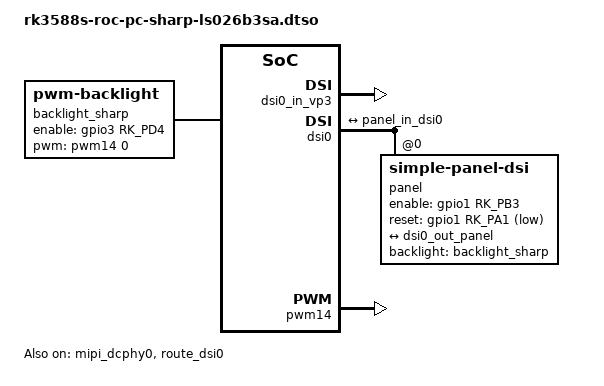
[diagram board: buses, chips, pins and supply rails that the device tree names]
// SPDX-License-Identifier: (GPL-2.0+ OR MIT)
/*
 * Sharp LS026B3SA 2160x2160 90Hz DSI panel overlay for ROC-RK3588S-PC
 * DSI0 via VP3, simple-panel-dsi with DSC, no lane polarity inversion
 */

/dts-v1/;
/plugin/;

#include <dt-bindings/gpio/gpio.h>
#include <dt-bindings/pinctrl/rockchip.h>
#include <dt-bindings/display/drm_mipi_dsi.h>

&{/} {
	backlight_sharp: backlight-sharp {
		compatible = "pwm-backlight";
		enable-gpios = <&gpio3 RK_PD4 GPIO_ACTIVE_HIGH>;
		pwms = <&pwm14 0 50000 1>;
		brightness-levels = <
			60  60  60  61  61  61  62  62
			62  63  63  63  64  64  64  65
			65  65  66  66  66  67  67  67
			68  68  68  69  69  69  70  70
			70  71  71  71  72  72  72  73
			73  73  74  74  74  75  75  75
			76  76  76  77  77  77  78  78
			78  79  79  79  80  80  80  81
			81  81  82  82  82  83  83  83
			84  84  84  85  85  85  86  86
			86  87  87  87  88  88  88  89
			89  89  90  91  92  93  94  95
			96  97  98  99 100 101 102 103
			104 105 106 107 108 109 110 111
			112 113 114 115 116 117 118 119
			120 121 122 123 124 125 126 127
			128 129 130 131 132 133 134 135
			136 137 138 139 140 141 142 143
			144 145 146 147 148 149 150 151
			152 153 154 155 156 157 158 159
			160 161 162 163 164 165 166 167
			168 169 170 171 172 173 174 175
			176 177 178 179 180 181 182 183
			184 185 186 187 188 189 190 191
			192 193 194 195 196 197 198 199
			200 201 202 203 204 205 206 207
			208 209 210 211 212 213 214 215
			216 217 218 219 220 221 222 223
			224 225 226 227 228 229 230 231
			232 233 234 235 236 237 238 239
			240 241 242 243 244 245 246 247
			248 249 250 251 252 253 254 255
		>;
		default-brightness-level = <150>;
	};
};

&mipi_dcphy0 {
	status = "okay";
};

&dsi0_in_vp2 {
	status = "disabled";
};

&dsi0_in_vp3 {
	status = "okay";
};

&route_dsi0 {
	status = "okay";
	connect = <&vp3_out_dsi0>;
};

&dsi0 {
	status = "okay";

	panel@0 {
		compatible = "simple-panel-dsi";
		reg = <0>;
		backlight = <&backlight_sharp>;

		enable-gpios = <&gpio1 RK_PB3 GPIO_ACTIVE_HIGH>;
		reset-gpios = <&gpio1 RK_PA1 GPIO_ACTIVE_LOW>;

		enable-delay-ms = <50>;
		prepare-delay-ms = <200>;
		reset-delay-ms = <50>;
		init-delay-ms = <55>;
		unprepare-delay-ms = <50>;
		disable-delay-ms = <20>;
		mipi-data-delay-ms = <200>;
		size,width = <46>;
		size,height = <46>;
		dsi,flags = <(MIPI_DSI_MODE_VIDEO | MIPI_DSI_MODE_VIDEO_BURST | MIPI_DSI_MODE_LPM)>;
		dsi,format = <MIPI_DSI_FMT_RGB888>;
		dsi,lanes = <4>;

		compressed-data;
		slice-width = <540>;
		slice-height = <16>;
		version-major = <1>;
		version-minor = <1>;

		panel-init-sequence = [
			/* PPS for VOP2 DSC encoder (type 0x0a = PICTURE_PARAMETER_SET) */
			0a 00 80
				11 00 00 89 30 80 08 70
				08 70 00 10 02 1c 02 1c
				02 00 02 0e 00 20 01 84
				00 07 00 0c 06 67 06 5c
				18 00 10 f0 03 0c 20 00
				06 0b 0b 33 0e 1c 2a 38
				46 54 62 69 70 77 79 7b
				7d 7e 01 02 01 00 09 40
				09 be 19 fc 19 fa 19 f8
				1a 38 1a 78 1a b6 2a f6
				2b 34 2b 74 3b 74 6b f4
				00 00 00 00 00 00 00 00
				00 00 00 00 00 00 00 00
				00 00 00 00 00 00 00 00
				00 00 00 00 00 00 00 00
				00 00 00 00 00 00 00 00
			/* Panel init commands */
			15 00 02 b0 00
			39 00 05 b9 13 5f 02 64
			39 00 03 ec 06 48
			39 00 03 ec 05 d8
			15 00 02 d6 00
			15 00 02 d2 0e
			39 00 03 be 00 0d
			15 00 02 f1 18
			39 00 05 d1 09 30 03 09
			15 00 02 f1 1a
			15 00 02 c2 07
			15 00 02 f1 08
			15 00 02 b6 60
			/* DSC PPS to panel via DCS register 0xE6 */
			39 00 81 e6
				11 00 00 89 30 80 08 70
				08 70 00 10 02 1c 02 1c
				02 00 02 0e 00 20 01 84
				00 07 00 0c 06 67 06 5c
				18 00 10 f0 03 0c 20 00
				06 0b 0b 33 0e 1c 2a 38
				46 54 62 69 70 77 79 7b
				7d 7e 01 02 01 00 09 40
				09 be 19 fc 19 fa 19 f8
				1a 38 1a 78 1a b6 2a f6
				2b 34 2b 74 3b 74 6b f4
				00 00 00 00 00 00 00 00
				00 00 00 00 00 00 00 00
				00 00 00 00 00 00 00 00
				00 00 00 00 00 00 00 00
				00 00 00 00 00 00 00 00
			15 00 02 35 00
			15 00 02 36 01
			15 00 02 26 01
			15 00 02 03 01
			05 78 01 11
			05 78 01 29
		];

		panel-exit-sequence = [
			05 32 01 28
			05 78 01 10
		];

		display-timings {
			native-mode = <&dsi_timing0>;
			dsi_timing0: timing0 {
				clock-frequency = <453966750>;
				hactive = <2160>;
				vactive = <2160>;
				hfront-porch = <54>;
				hsync-len = <20>;
				hback-porch = <33>;
				vfront-porch = <57>;
				vsync-len = <4>;
				vback-porch = <4>;
				hsync-active = <0>;
				vsync-active = <0>;
				de-active = <0>;
				pixelclk-active = <0>;
			};
		};

		ports {
			#address-cells = <1>;
			#size-cells = <0>;
			port@0 {
				reg = <0>;
				panel_in_dsi0: endpoint {
					remote-endpoint = <&dsi0_out_panel>;
				};
			};
		};
	};

	ports {
		#address-cells = <1>;
		#size-cells = <0>;
		port@1 {
			reg = <1>;
			dsi0_out_panel: endpoint {
				remote-endpoint = <&panel_in_dsi0>;
			};
		};
	};
};

&pwm14 {
	pinctrl-0 = <&pwm14m2_pins>;
	status = "okay";
};
